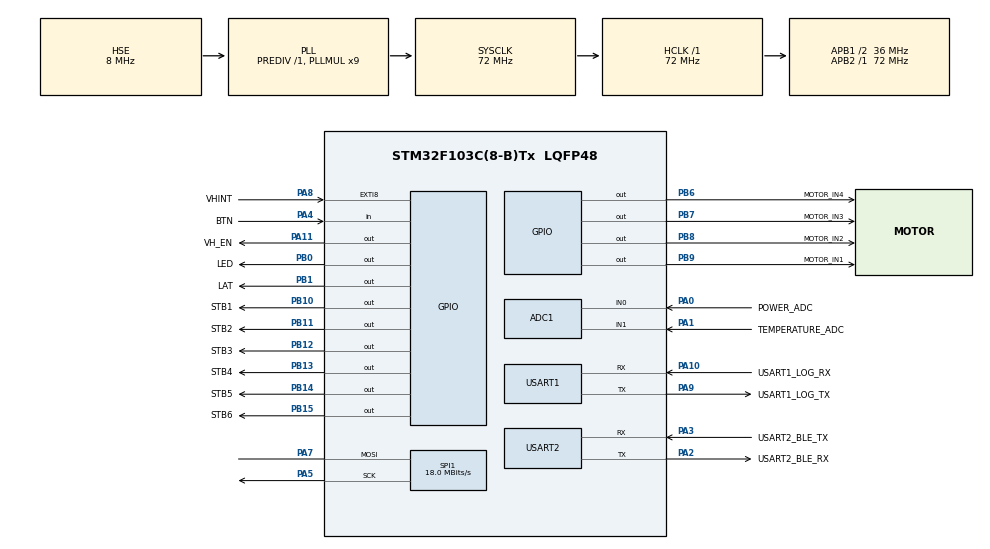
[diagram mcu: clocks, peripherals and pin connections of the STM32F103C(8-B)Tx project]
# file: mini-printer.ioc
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ADC1.Channel-0\#ChannelRegularConversion=ADC_CHANNEL_0
ADC1.Channel-1\#ChannelRegularConversion=ADC_CHANNEL_1
ADC1.ContinuousConvMode=DISABLE
ADC1.DataAlign=ADC_DATAALIGN_RIGHT
ADC1.DiscontinuousConvMode=ENABLE
ADC1.NbrOfConversion=2
ADC1.NbrOfConversionFlag=1
ADC1.Rank-0\#ChannelRegularConversion=1
ADC1.Rank-1\#ChannelRegularConversion=2
ADC1.SamplingTime-0\#ChannelRegularConversion=ADC_SAMPLETIME_239CYCLES_5
ADC1.SamplingTime-1\#ChannelRegularConversion=ADC_SAMPLETIME_239CYCLES_5
ADC1.master=1
FREERTOS.Tasks01=defaultTask,0,128,StartDefaultTask,Default,NULL,Dynamic,NULL,NULL
FREERTOS.configTOTAL_HEAP_SIZE=2072
FREERTOS.configUSE_TIMERS=1
Mcu.Family=STM32F1
Mcu.Name=STM32F103C(8-B)Tx
Mcu.Package=LQFP48
NVIC.EXTI9_5_IRQn=true\:5\:0\:true\:false\:true\:false\:true\:true\:true
NVIC.PriorityGroup=NVIC_PRIORITYGROUP_4
NVIC.TIM4_IRQn=true\:15\:0\:false\:false\:true\:false\:false\:true\:true
NVIC.TimeBase=TIM4_IRQn
NVIC.TimeBaseIP=TIM4
NVIC.USART2_IRQn=true\:5\:0\:false\:false\:true\:true\:true\:true\:true
PA0-WKUP.GPIO_Label=POWER_ADC
PA0-WKUP.Signal=ADCx_IN0
PA1.GPIO_Label=TEMPERATURE_ADC
PA1.Signal=ADCx_IN1
PA10.GPIO_Label=USART1_LOG_RX
PA10.GPIO_PuPd=GPIO_NOPULL
PA10.Mode=Asynchronous
PA10.Signal=USART1_RX
PA11.GPIO_Label=VH_EN
PA11.Signal=GPIO_Output
PA13.Mode=Serial_Wire
PA13.Signal=SYS_JTMS-SWDIO
PA14.Mode=Serial_Wire
PA14.Signal=SYS_JTCK-SWCLK
PA2.GPIO_Label=USART2_BLE_RX
PA2.Mode=Asynchronous
PA2.Signal=USART2_TX
PA3.GPIO_Label=USART2_BLE_TX
PA3.GPIO_PuPd=GPIO_NOPULL
PA3.Mode=Asynchronous
PA3.Signal=USART2_RX
PA4.GPIO_Label=BTN
PA4.GPIO_PuPd=GPIO_PULLUP
PA4.Signal=GPIO_Input
PA5.Mode=Simplex_Bidirectional_Master
PA5.Signal=SPI1_SCK
PA7.Mode=Simplex_Bidirectional_Master
PA7.Signal=SPI1_MOSI
PA8.GPIO_Label=VHINT
PA8.Signal=GPXTI8
PA9.GPIO_Label=USART1_LOG_TX
PA9.Mode=Asynchronous
PA9.Signal=USART1_TX
PB0.GPIO_Label=LED
PB0.GPIO_PuPd=GPIO_PULLUP
PB0.Signal=GPIO_Output
PB1.GPIO_Label=LAT
PB1.GPIO_PuPd=GPIO_PULLUP
PB1.PinState=GPIO_PIN_SET
PB1.Signal=GPIO_Output
PB10.GPIO_Label=STB1
PB10.Signal=GPIO_Output
PB11.GPIO_Label=STB2
PB11.Signal=GPIO_Output
PB12.GPIO_Label=STB3
PB12.Signal=GPIO_Output
PB13.GPIO_Label=STB4
PB13.Signal=GPIO_Output
PB14.GPIO_Label=STB5
PB14.Signal=GPIO_Output
PB15.GPIO_Label=STB6
PB15.Signal=GPIO_Output
PB6.GPIO_Label=MOTOR_IN4
PB6.Signal=GPIO_Output
PB7.GPIO_Label=MOTOR_IN3
PB7.Signal=GPIO_Output
PB8.GPIO_Label=MOTOR_IN2
PB8.Signal=GPIO_Output
PB9.GPIO_Label=MOTOR_IN1
PB9.Signal=GPIO_Output
PD0-OSC_IN.Mode=HSE-External-Oscillator
PD0-OSC_IN.Signal=RCC_OSC_IN
PD1-OSC_OUT.Mode=HSE-External-Oscillator
PD1-OSC_OUT.Signal=RCC_OSC_OUT
ProjectManager.HeapSize=0x200
ProjectManager.StackSize=0x400
ProjectManager.TargetToolchain=Makefile
RCC.ADCPresc=RCC_ADCPCLK2_DIV6
RCC.AHBFreq_Value=72000000
RCC.APB1CLKDivider=RCC_HCLK_DIV2
RCC.APB1Freq_Value=36000000
RCC.APB1TimFreq_Value=72000000
RCC.APB2Freq_Value=72000000
RCC.APB2TimFreq_Value=72000000
RCC.HCLKFreq_Value=72000000
RCC.PLLMUL=RCC_PLL_MUL9
RCC.PLLSourceVirtual=RCC_PLLSOURCE_HSE
RCC.SYSCLKFreq_VALUE=72000000
RCC.SYSCLKSource=RCC_SYSCLKSOURCE_PLLCLK
RCC.USBFreq_Value=72000000
SH.ADCx_IN0.0=ADC1_IN0,IN0
SH.ADCx_IN1.0=ADC1_IN1,IN1
SPI1.BaudRatePrescaler=SPI_BAUDRATEPRESCALER_4
SPI1.CalculateBaudRate=18.0 MBits/s
SPI1.Direction=SPI_DIRECTION_1LINE
SPI1.Mode=SPI_MODE_MASTER
SPI1.VirtualType=VM_MASTER
TIM1.Prescaler=71
USART1.VirtualMode=VM_ASYNC
USART2.VirtualMode=VM_ASYNC
VP_FREERTOS_VS_CMSIS_V1.Mode=CMSIS_V1
VP_SYS_VS_tim4.Mode=TIM4
VP_TIM1_VS_ClockSourceINT.Mode=Internal
board=custom

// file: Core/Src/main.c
/* USER CODE BEGIN Header */
/**
  ******************************************************************************
  * @file           : main.c
  * @brief          : Main program body
  ******************************************************************************
  * @attention
  *
  * Copyright (c) 2025 STMicroelectronics.
  * All rights reserved.
  *
  * This software is licensed under terms that can be found in the LICENSE file
  * in the root directory of this software component.
  * If no LICENSE file comes with this software, it is provided AS-IS.
  *
  ******************************************************************************
  */
/* USER CODE END Header */
#include "main.h"
#include "cmsis_os.h"
#include "adc.h"
#include "spi.h"
#include "tim.h"
#include "usart.h"
#include "gpio.h"

/* USER CODE BEGIN Includes */
#include "stdio.h"
#include "em_task.h"
/* USER CODE END Includes */

void SystemClock_Config(void);
void MX_FREERTOS_Init(void);

/* USER CODE BEGIN 0 */
extern uint8_t aRxBuffer;
/* USER CODE END 0 */

int main(void)
{

  /* MCU Configuration--------------------------------------------------------*/

  /* Reset of all peripherals, Initializes the Flash interface and the Systick. */
  HAL_Init();

  /* Configure the system clock */
  SystemClock_Config();

  /* Initialize all configured peripherals */
  MX_GPIO_Init();
  MX_ADC1_Init();
  MX_SPI1_Init();
  MX_USART1_UART_Init();
  MX_USART2_UART_Init();
  MX_TIM1_Init();
  /* USER CODE BEGIN 2 */
  // new code`````````````````````````````
	printf("----app init v1.0.9----\n");
	HAL_UART_Receive_IT(&huart2, (uint8_t *)&aRxBuffer, 1);
	init_task();
 /* USER CODE END 2 */

  /* Call init function for freertos objects (in cmsis_os2.c) */
  MX_FREERTOS_Init();

  /* Start scheduler */
  osKernelStart();

  /* We should never get here as control is now taken by the scheduler */

  /* Infinite loop */
  while (1)
  {

  }
}

void SystemClock_Config(void)
{
  RCC_OscInitTypeDef RCC_OscInitStruct = {0};
  RCC_ClkInitTypeDef RCC_ClkInitStruct = {0};
  RCC_PeriphCLKInitTypeDef PeriphClkInit = {0};

  /** Initializes the RCC Oscillators according to the specified parameters
  * in the RCC_OscInitTypeDef structure.
  */
  RCC_OscInitStruct.OscillatorType = RCC_OSCILLATORTYPE_HSE;
  RCC_OscInitStruct.HSEState = RCC_HSE_ON;
  RCC_OscInitStruct.HSEPredivValue = RCC_HSE_PREDIV_DIV1;
  RCC_OscInitStruct.HSIState = RCC_HSI_ON;
  RCC_OscInitStruct.PLL.PLLState = RCC_PLL_ON;
  RCC_OscInitStruct.PLL.PLLSource = RCC_PLLSOURCE_HSE;
  RCC_OscInitStruct.PLL.PLLMUL = RCC_PLL_MUL9;
  if (HAL_RCC_OscConfig(&RCC_OscInitStruct) != HAL_OK)
  {
    Error_Handler();
  }

  /** Initializes the CPU, AHB and APB buses clocks
  */
  RCC_ClkInitStruct.ClockType = RCC_CLOCKTYPE_HCLK|RCC_CLOCKTYPE_SYSCLK
                              |RCC_CLOCKTYPE_PCLK1|RCC_CLOCKTYPE_PCLK2;
  RCC_ClkInitStruct.SYSCLKSource = RCC_SYSCLKSOURCE_PLLCLK;
  RCC_ClkInitStruct.AHBCLKDivider = RCC_SYSCLK_DIV1;
  RCC_ClkInitStruct.APB1CLKDivider = RCC_HCLK_DIV2;
  RCC_ClkInitStruct.APB2CLKDivider = RCC_HCLK_DIV1;

  if (HAL_RCC_ClockConfig(&RCC_ClkInitStruct, FLASH_LATENCY_2) != HAL_OK)
  {
    Error_Handler();
  }
  PeriphClkInit.PeriphClockSelection = RCC_PERIPHCLK_ADC;
  PeriphClkInit.AdcClockSelection = RCC_ADCPCLK2_DIV6;
  if (HAL_RCCEx_PeriphCLKConfig(&PeriphClkInit) != HAL_OK)
  {
    Error_Handler();
  }
}

/* USER CODE BEGIN 4 */

// new code-----------------------------------------------
#include "usart.h"  // Provides access to the huart1 UART handle for printf redirection

/**
 * @brief  Low-level write function used by the C library (newlib) for printf().
 *
 * This function is called internally by printf() and other formatted output functions.
 * It transmits a string of characters over USART1 by using HAL_UART_Transmit.
 *
 * By overriding _write(), we enable printf() to send output to a UART terminal,
 * such as through a USB-to-Serial adapter connected to USART1 TX.
 *
 * @param file  File descriptor (ignored in this context)
 * @param ptr   Pointer to the character buffer to send
 * @param len   Number of characters to send
 * @retval int  The number of bytes written
 */
int _write(int file, char *ptr, int len)
{
  // Send the entire buffer over USART1
  HAL_UART_Transmit(&huart1, (uint8_t *)ptr, len, HAL_MAX_DELAY);

  // Return number of bytes written
  return len;
}

/* USER CODE END 4 */

void HAL_TIM_PeriodElapsedCallback(TIM_HandleTypeDef *htim)
{
  if (htim->Instance == TIM4)
  {
    HAL_IncTick();
  }
}

void Error_Handler(void)
{
  __disable_irq();
  while (1)
  {
  }
}
